# MIMXRT1011 register map
Vendor: nxp.com; File version: 1.0
CPU: CM7 r0p1, little endian, MPU, FPU, VTOR, 4 interrupt priority bits
Registers are 32-bit, read-write, reset 0x0 unless marked. A register's access mark holds for its fields unless they carry their own. Offsets are from the block's base; [hi:lo] are bit positions; {n}, {i} and the like mark numbered series; 'fields as' and 'values as' point back to an identical list.

## FLEXSPI
Base 0x400A0000
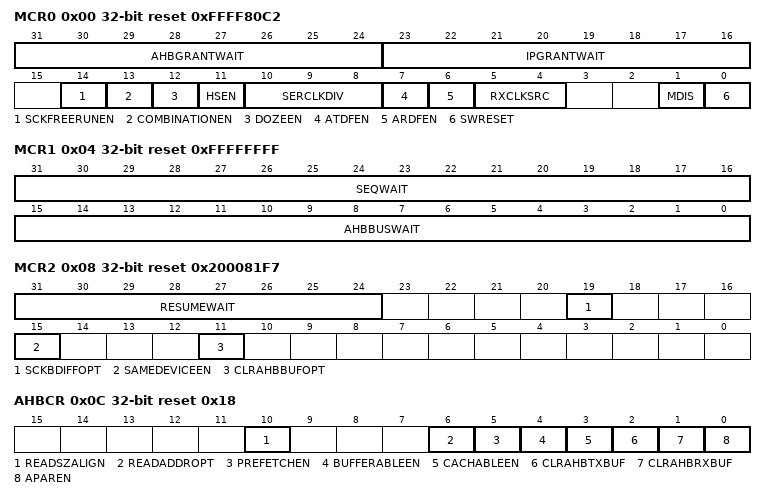
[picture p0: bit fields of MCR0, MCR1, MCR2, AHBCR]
0x00 MCR0 reset 0xFFFF80C2 — Module Control Register 0
  [31:24] AHBGRANTWAIT — Timeout wait cycle for AHB command grant.
  [23:16] IPGRANTWAIT — Time out wait cycle for IP command grant.
  [14] SCKFREERUNEN — This bit is used to force SCLK output free-running. For FPGA applications, external device may use SCLK as reference clock to its internal PLL. If SCLK free-running is enabled, data sampling with loopback clock from SCLK pad is not supported (MCR0[RXCLKSRC]=2).
    0=DISABLE; 1=ENABLE
  [13] COMBINATIONEN — This bit is to support Flash Octal mode access by combining Port A and B Data pins (A_DATA[3:0] and B_DATA[3:0]), when Port A and Port B are of 4 bit data width.
    0=DISABLE; 1=ENABLE
  [12] DOZEEN — Doze mode enable bit
    0=Doze mode support disabled. AHB clock and serial clock will not be gated off when there is doze mode request from system.; 1=Doze mode support enabled. AHB clock and serial clock will be gated off when there is doze mode request from system.
  [11] HSEN — Half Speed Serial Flash access Enable.
    0=Disable divide by 2 of serial flash clock for half speed commands; 1=Enable divide by 2 of serial flash clock for half speed commands
  [10:8] SERCLKDIV — The serial root clock could be divided inside FlexSPI . See Clocks section for more details on clocking.
    {v}=Divided by {v+1} (v=0..7)
  [7] ATDFEN — Enable AHB bus Write Access to IP TX FIFO.
    0=IP TX FIFO should be written by IP Bus. AHB Bus write access to IP TX FIFO memory space will get bus error response.; 1=IP TX FIFO should be written by AHB Bus. IP Bus write access to IP TX FIFO memory space will be ignored but no bus error response.
  [6] ARDFEN — Enable AHB bus Read Access to IP RX FIFO.
    0=IP RX FIFO should be read by IP Bus. AHB Bus read access to IP RX FIFO memory space will get bus error response.; 1=IP RX FIFO should be read by AHB Bus. IP Bus read access to IP RX FIFO memory space will always return data zero but no bus error response.
  [5:4] RXCLKSRC — Sample Clock source selection for Flash Reading
    0=Dummy Read strobe generated by FlexSPI Controller and loopback internally; 1=Dummy Read strobe generated by FlexSPI Controller and loopback from DQS pad; 3=Flash provided Read strobe and input from DQS pad
  [1] MDIS — Module Disable
  [0] SWRESET — Software Reset
0x04 MCR1 reset 0xFFFFFFFF — Module Control Register 1
  [31:16] SEQWAIT — Command Sequence Execution will timeout and abort after SEQWAIT * 1024 Serial Root Clock cycles
  [15:0] AHBBUSWAIT — AHB Read/Write access to Serial Flash Memory space will timeout if not data received from Flash or data not transmitted after AHBBUSWAIT * 1024 ahb clock cycles, AHB Bus will get an error response
0x08 MCR2 reset 0x200081F7 — Module Control Register 2
  [31:24] RESUMEWAIT — Wait cycle (in AHB clock cycle) for idle state before suspended command sequence resumed.
  [19] SCKBDIFFOPT — B_SCLK pad can be used as A_SCLK differential clock output (inverted clock to A_SCLK). In this case, port B flash access is not available. After changing the value of this field, MCR0[SWRESET] should be set.
    0=B_SCLK pad is used as port B SCLK clock output. Port B flash access is available.; 1=B_SCLK pad is used as port A SCLK inverted clock output (Differential clock to A_SCLK). Port B flash access is not available.
  [15] SAMEDEVICEEN — All external devices are same devices (both in types and size) for A1/A2/B1/B2.
    0=individual_parallel (In Individual mode, FLSHA1CRx/FLSHA2CRx/FLSHB1CRx/FLSHB2CRx register setting will be applied to Flash A1/A2/B1/B2 separately. In Parallel mode, FLSHA1CRx register setting will be applied to Flash A1 and B1, FLSHA2CRx register setting will be applied to Flash A2 and B2. FLSHB1CRx/FLSHB2CRx register settings will be ignored.); 1=ENABLE (FLSHA1CR0/FLSHA1CR1/FLSHA1CR2 register settings will be applied to Flash A1/A2/B1/B2. FLSHA2CRx/FLSHB1CRx/FLSHB2CRx will be ignored.)
  [11] CLRAHBBUFOPT — This bit determines whether AHB RX Buffer and AHB TX Buffer will be cleaned automatically when FlexSPI returns STOP mode ACK. Software should set this bit if AHB RX Buffer or AHB TX Buffer will be powered off in STOP mode. Otherwise AHB read access after exiting STOP mode may hit AHB RX Buffer or AHB TX Buffer but their data entries are invalid.
    0=AHB RX/TX Buffer will not be cleaned automatically when FlexSPI return Stop mode ACK; 1=AHB RX/TX Buffer will be cleaned automatically when FlexSPI return Stop mode ACK
0x0C AHBCR reset 0x18 — AHB Bus Control Register
  [10] READSZALIGN — AHB Read Size Alignment
    0=AHB read size will be decided by other register setting like PREFETCH_EN,OTFAD_EN; 1=AHB read size to up size to 8 bytes aligned, no prefetching
  [6] READADDROPT — AHB Read Address option bit. This option bit is intend to remove AHB burst start address alignment limitation.
    0=There is AHB read burst start address alignment limitation when flash is accessed in parallel mode or flash is word-addressable; 1=There is no AHB read burst start address alignment limitation. FlexSPI will fetch more data than AHB burst required to meet the alignment requirement.
  [5] PREFETCHEN — AHB Read Prefetch Enable.
  [4] BUFFERABLEEN — Enable AHB bus bufferable write access support. This field affects the last beat of AHB write access, refer for more details about AHB bufferable write.
    0=Disabled. For all AHB write access (no matter bufferable or non-bufferable ), FlexSPI will return AHB Bus ready after all data is transmitted to External device and AHB command finished.; 1=Enabled. For AHB bufferable write access, FlexSPI will return AHB Bus ready when the AHB command is granted by arbitrator and will not wait for AHB command finished.
  [3] CACHABLEEN — Enable AHB bus cachable read access support.
    0=Disabled. When there is AHB bus cachable read access, FlexSPI will not check whether it hit AHB TX Buffer.; 1=Enabled. When there is AHB bus cachable read access, FlexSPI will check whether it hit AHB TX Buffer first.
  [2] CLRAHBTXBUF — Clear the status/pointers of AHB TX Buffer. Auto-cleared. For internal use only.
  [1] CLRAHBRXBUF — Clear the status/pointers of AHB RX Buffer. Auto-cleared.
  [0] APAREN — Parallel mode enabled for AHB triggered Command (both read and write) .
    0=individual (Flash will be accessed in Individual mode.); 1=ENABLE (Flash will be accessed in Parallel mode.)
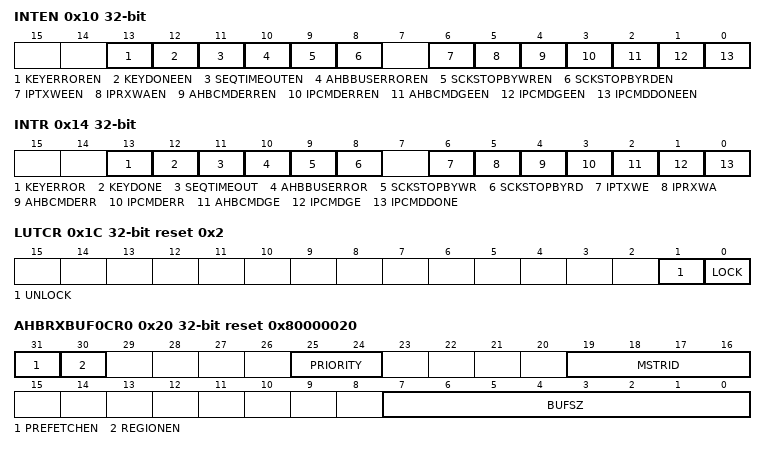
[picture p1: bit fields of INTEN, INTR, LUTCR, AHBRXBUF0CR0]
0x10 INTEN — Interrupt Enable Register
  [13] KEYERROREN — OTFAD key blob processing error interrupt enable.Refer Interrupts chapter for more details.
  [12] KEYDONEEN — OTFAD key blob processing done interrupt enable.Refer Interrupts chapter for more details.
  [11] SEQTIMEOUTEN — Sequence execution timeout interrupt enable.Refer Interrupts chapter for more details.
  [10] AHBBUSERROREN — AHB Bus error interrupt enable.Refer Interrupts chapter for more details.
  [9] SCKSTOPBYWREN — SCLK is stopped during command sequence because Async TX FIFO empty interrupt enable.
  [8] SCKSTOPBYRDEN — SCLK is stopped during command sequence because Async RX FIFO full interrupt enable.
  [6] IPTXWEEN — IP TX FIFO WaterMark empty interrupt enable.
  [5] IPRXWAEN — IP RX FIFO WaterMark available interrupt enable.
  [4] AHBCMDERREN — AHB triggered Command Sequences Error Detected interrupt enable.
  [3] IPCMDERREN — IP triggered Command Sequences Error Detected interrupt enable.
  [2] AHBCMDGEEN — AHB triggered Command Sequences Grant Timeout interrupt enable.
  [1] IPCMDGEEN — IP triggered Command Sequences Grant Timeout interrupt enable.
  [0] IPCMDDONEEN — IP triggered Command Sequences Execution finished interrupt enable.
0x14 INTR — Interrupt Register
  [13] KEYERROR ro — OTFAD key blob processing error interrupt.
  [12] KEYDONE write-1-clears — OTFAD key blob processing done interrupt.
  [11] SEQTIMEOUT write-1-clears — Sequence execution timeout interrupt.
  [10] AHBBUSERROR write-1-clears — AHB Bus timeout or AHB bus illegal access Flash during OTFAD key blob processing interrupt.
  [9] SCKSTOPBYWR write-1-clears — SCLK is stopped during command sequence because Async TX FIFO empty interrupt.
  [8] SCKSTOPBYRD write-1-clears — SCLK is stopped during command sequence because Async RX FIFO full interrupt.
  [6] IPTXWE write-1-clears — IP TX FIFO watermark empty interrupt.
  [5] IPRXWA write-1-clears — IP RX FIFO watermark available interrupt.
  [4] AHBCMDERR write-1-clears — AHB triggered Command Sequences Error Detected interrupt. When an error detected for AHB command, this command will be ignored and not executed at all.
  [3] IPCMDERR write-1-clears — IP triggered Command Sequences Error Detected interrupt. When an error detected for IP command, this command will be ignored and not executed at all.
  [2] AHBCMDGE write-1-clears — AHB triggered Command Sequences Grant Timeout interrupt.
  [1] IPCMDGE write-1-clears — IP triggered Command Sequences Grant Timeout interrupt.
  [0] IPCMDDONE write-1-clears — IP triggered Command Sequences Execution finished interrupt. This interrupt is also generated when there is IPCMDGE or IPCMDERR interrupt generated.
0x18 LUTKEY reset 0x5AF05AF0
  [31:0] KEY — The Key to lock or unlock LUT.
0x1C LUTCR reset 0x2 — LUT Control Register
  [1] UNLOCK — Unlock LUT
  [0] LOCK — Lock LUT
0x20 AHBRXBUF0CR0 reset 0x80000020 — AHB RX Buffer 0 Control Register 0
  [31] PREFETCHEN — AHB Read Prefetch Enable for current AHB RX Buffer corresponding Master.
  [30] REGIONEN — AHB RX Buffer address region funciton enable
  [25:24] PRIORITY — This priority for AHB Master Read which this AHB RX Buffer is assigned. 7 is the highest priority, 0 the lowest.
  [19:16] MSTRID — This AHB RX Buffer is assigned according to AHB Master with ID (MSTR_ID).
  [7:0] BUFSZ — AHB RX Buffer Size in 64 bits.
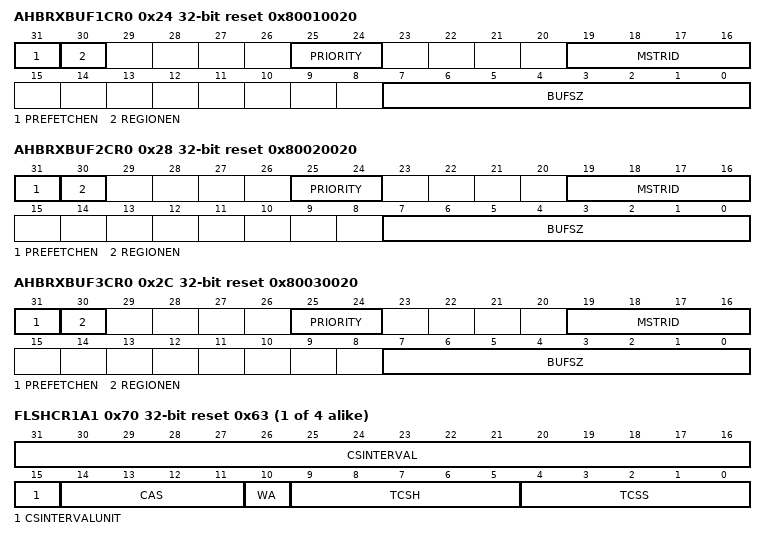
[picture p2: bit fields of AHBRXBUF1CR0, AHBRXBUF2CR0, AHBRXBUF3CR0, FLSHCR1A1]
0x24 AHBRXBUF1CR0 reset 0x80010020 — AHB RX Buffer 1 Control Register 0
  fields as AHBRXBUF0CR0
0x28 AHBRXBUF2CR0 reset 0x80020020 — AHB RX Buffer 2 Control Register 0
  fields as AHBRXBUF0CR0
0x2C AHBRXBUF3CR0 reset 0x80030020 — AHB RX Buffer 3 Control Register 0
  fields as AHBRXBUF0CR0
0x60 FLSHA1CR0 reset 0x10000 — Flash Control Register 0
  [22:0] FLSHSZ — Flash Size in KByte.
0x64 FLSHA2CR0 reset 0x10000 — Flash Control Register 0
  [22:0] FLSHSZ — Flash Size in KByte.
0x68 FLSHB1CR0 reset 0x10000 — Flash Control Register 0
  [22:0] FLSHSZ — Flash Size in KByte.
0x6C FLSHB2CR0 reset 0x10000 — Flash Control Register 0
  [22:0] FLSHSZ — Flash Size in KByte.
0x70 FLSHCR1{x} (x=A1,A2,B1,B2; step 0x4) reset 0x63 — Flash Control Register 1
  [31:16] CSINTERVAL — This field is used to set the minimum interval between flash device Chip selection deassertion and flash device Chip selection assertion. If external flash has a limitation on the interval between command sequences, this field should be set accordingly. If there is no limitation, set this field with value 0x0.
  [15] CSINTERVALUNIT
    0=The CS interval unit is 1 serial clock cycle; 1=The CS interval unit is 256 serial clock cycle
  [14:11] CAS — Column Address Size.
  [10] WA — Word Addressable.
  [9:5] TCSH — Serial Flash CS Hold time.
  [4:0] TCSS — Serial Flash CS setup time.
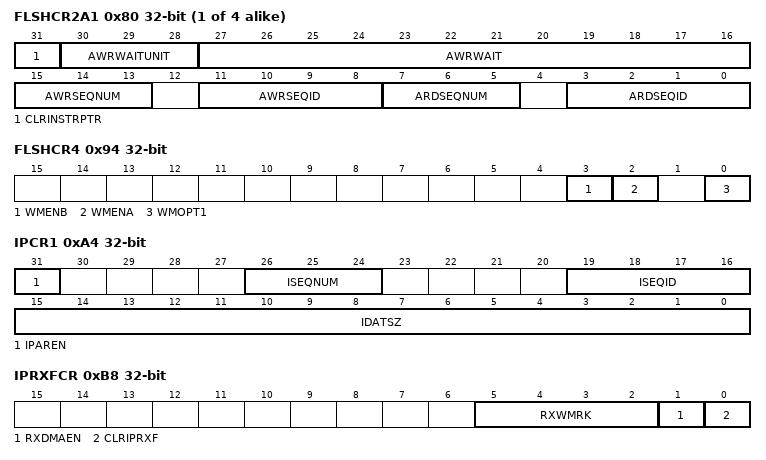
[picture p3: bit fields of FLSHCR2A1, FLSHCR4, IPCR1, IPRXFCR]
0x80 FLSHCR2{x} (x=A1,A2,B1,B2; step 0x4) — Flash Control Register 2
  [31] CLRINSTRPTR — Clear the instruction pointer which is internally saved pointer by JMP_ON_CS. Refer Programmable Sequence Engine for details.
  [30:28] AWRWAITUNIT
    0=The AWRWAIT unit is 2 ahb clock cycle; 1=The AWRWAIT unit is 8 ahb clock cycle; 2=The AWRWAIT unit is 32 ahb clock cycle; 3=The AWRWAIT unit is 128 ahb clock cycle; 4=The AWRWAIT unit is 512 ahb clock cycle; 5=The AWRWAIT unit is 2048 ahb clock cycle; 6=The AWRWAIT unit is 8192 ahb clock cycle; 7=The AWRWAIT unit is 32768 ahb clock cycle
  [27:16] AWRWAIT — For certain devices (such as FPGA), it need some time to write data into internal memory after the command sequences finished on FlexSPI interface
  [15:13] AWRSEQNUM — Sequence Number for AHB Write triggered Command.
  [11:8] AWRSEQID — Sequence Index for AHB Write triggered Command.
  [7:5] ARDSEQNUM — Sequence Number for AHB Read triggered Command in LUT.
  [3:0] ARDSEQID — Sequence Index for AHB Read triggered Command in LUT.
0x94 FLSHCR4 — Flash Control Register 4
  [3] WMENB — Write mask enable bit for flash device on port B. When write mask function is needed for memory device on port B, this bit must be set.
    0=Write mask is disabled, DQS(RWDS) pin will be un-driven when writing to external device; 1=Write mask is enabled, DQS(RWDS) pin will be driven by FlexSPI as write mask output when writing to external device
  [2] WMENA — Write mask enable bit for flash device on port A. When write mask function is needed for memory device on port A, this bit must be set.
    values as WMENB
  [0] WMOPT1 — Write mask option bit 1. This option bit could be used to remove AHB write burst start address alignment limitation.
    0=DISABLE (DQS pin will be used as Write Mask when writing to external device. There is no limitation on AHB write burst start address alignment when flash is accessed in individual mode.); 1=ENABLE (DQS pin will not be used as Write Mask when writing to external device. There is limitation on AHB write burst start address alignment when flash is accessed in individual mode.)
0xA0 IPCR0 — IP Control Register 0
  [31:0] SFAR — Serial Flash Address for IP command.
0xA4 IPCR1 — IP Control Register 1
  [31] IPAREN — Parallel mode Enabled for IP command.
    0=DISABLE (Flash will be accessed in Individual mode.); 1=ENABLE (Flash will be accessed in Parallel mode.)
  [26:24] ISEQNUM — Sequence Number for IP command: ISEQNUM+1.
  [19:16] ISEQID — Sequence Index in LUT for IP command.
  [15:0] IDATSZ — Flash Read/Program Data Size (in Bytes) for IP command.
0xB0 IPCMD — IP Command Register
  [0] TRG — Setting this bit will trigger an IP Command.
0xB8 IPRXFCR — IP RX FIFO Control Register
  [5:2] RXWMRK — Watermark level is (RXWMRK+1)*64 Bits.
  [1] RXDMAEN — IP RX FIFO reading by DMA enabled.
    0=IP RX FIFO would be read by processor; 1=IP RX FIFO would be read by DMA
  [0] CLRIPRXF — Clear all valid data entries in IP RX FIFO.
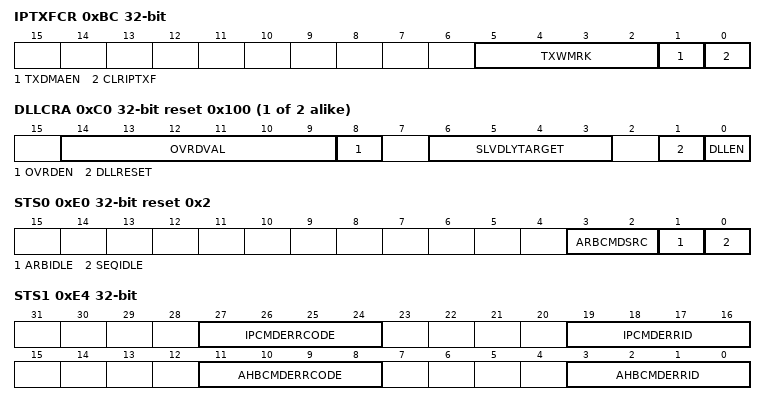
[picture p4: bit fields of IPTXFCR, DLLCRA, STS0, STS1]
0xBC IPTXFCR — IP TX FIFO Control Register
  [5:2] TXWMRK — Watermark level is (TXWMRK+1)*64 Bits.
  [1] TXDMAEN — IP TX FIFO filling by DMA enabled.
    0=IP TX FIFO would be filled by processor; 1=IP TX FIFO would be filled by DMA
  [0] CLRIPTXF — Clear all valid data entries in IP TX FIFO.
0xC0 DLLCR{x} (x=A,B; step 0x4) reset 0x100 — DLL Control Register 0
  [14:9] OVRDVAL — Slave clock delay line delay cell number selection override value.
  [8] OVRDEN — Slave clock delay line delay cell number selection override enable.
  [6:3] SLVDLYTARGET — The delay target for slave delay line is: ((SLVDLYTARGET+1) * 1/32 * clock cycle of reference clock (serial root clock). If serial root clock is >= 100 MHz, DLLEN set to 0x1, OVRDEN set to =0x0, then SLVDLYTARGET setting of 0xF is recommended.
  [1] DLLRESET — Software could force a reset on DLL by setting this field to 0x1. This will cause the DLL to lose lock and re-calibrate to detect an ref_clock half period phase shift. The reset action is edge triggered, so software need to clear this bit after set this bit (no delay limitation).
  [0] DLLEN — DLL calibration enable.
0xE0 STS0 ro reset 0x2 — Status Register 0
  [3:2] ARBCMDSRC — This status field indicates the trigger source of current command sequence granted by arbitrator. This field value is meaningless when ARB_CTL is not busy (STS0[ARBIDLE]=0x1).
    0=Triggered by AHB read command (triggered by AHB read); 1=Triggered by AHB write command (triggered by AHB Write); 2=Triggered by IP command (triggered by setting register bit IPCMD.TRG); 3=Triggered by suspended command (resumed)
  [1] ARBIDLE — This status bit indicates the state machine in ARB_CTL is busy and there is command sequence granted by arbitrator and not finished yet on FlexSPI interface. When ARB_CTL state (ARBIDLE=0x1) is idle, there will be no transaction on FlexSPI interface also (SEQIDLE=0x1). So this bit should be polled to wait for FlexSPI controller become idle instead of SEQIDLE.
  [0] SEQIDLE — This status bit indicates the state machine in SEQ_CTL is idle and there is command sequence executing on FlexSPI interface.
0xE4 STS1 ro — Status Register 1
  [27:24] IPCMDERRCODE — Indicates the Error Code when IP command Error detected. This field will be cleared when INTR[IPCMDERR] is write-1-clear(w1c).
    0=No error; 2=IP command with JMP_ON_CS instruction used in the sequence; 3=There is unknown instruction opcode in the sequence; 4=Instruction DUMMY_SDR/DUMMY_RWDS_SDR used in DDR sequence; 5=Instruction DUMMY_DDR/DUMMY_RWDS_DDR used in SDR sequence; 6=Flash access start address exceed the whole flash address range (A1/A2/B1/B2); 14=Sequence execution timeout; 15=Flash boundary crossed
  [19:16] IPCMDERRID — Indicates the sequence Index when IP command error detected. This field will be cleared when INTR[IPCMDERR] is write-1-clear(w1c).
  [11:8] AHBCMDERRCODE — Indicates the Error Code when AHB command Error detected. This field will be cleared when INTR[AHBCMDERR] is write-1-clear(w1c).
    0=No error; 2=AHB Write command with JMP_ON_CS instruction used in the sequence; 3=There is unknown instruction opcode in the sequence; 4=Instruction DUMMY_SDR/DUMMY_RWDS_SDR used in DDR sequence; 5=Instruction DUMMY_DDR/DUMMY_RWDS_DDR used in SDR sequence; 14=Sequence execution timeout
  [3:0] AHBCMDERRID — Indicates the sequence index when an AHB command error is detected. This field will be cleared when INTR[AHBCMDERR] is write-1-clear(w1c).
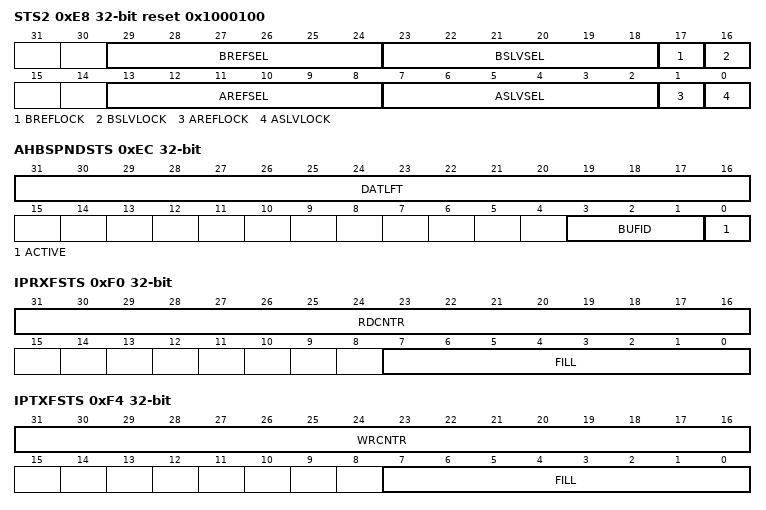
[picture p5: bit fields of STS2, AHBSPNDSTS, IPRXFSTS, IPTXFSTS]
0xE8 STS2 ro reset 0x1000100 — Status Register 2
  [29:24] BREFSEL — Flash B sample clock reference delay line delay cell number selection.
  [23:18] BSLVSEL — Flash B sample clock slave delay line delay cell number selection.
  [17] BREFLOCK — Flash B sample clock reference delay line locked.
  [16] BSLVLOCK — Flash B sample clock slave delay line locked.
  [13:8] AREFSEL — Flash A sample clock reference delay line delay cell number selection.
  [7:2] ASLVSEL — Flash A sample clock slave delay line delay cell number selection .
  [1] AREFLOCK — Flash A sample clock reference delay line locked.
  [0] ASLVLOCK — Flash A sample clock slave delay line locked.
0xEC AHBSPNDSTS ro — AHB Suspend Status Register
  [31:16] DATLFT — Left Data size for suspended command sequence (in byte).
  [3:1] BUFID — AHB RX BUF ID for suspended command sequence.
  [0] ACTIVE — Indicates if an AHB read prefetch command sequence has been suspended.
0xF0 IPRXFSTS ro — IP RX FIFO Status Register
  [31:16] RDCNTR — Total Read Data Counter: RDCNTR * 64 Bits.
  [7:0] FILL — Fill level of IP RX FIFO.
0xF4 IPTXFSTS ro — IP TX FIFO Status Register
  [31:16] WRCNTR — Total Write Data Counter: WRCNTR * 64 Bits.
  [7:0] FILL — Fill level of IP TX FIFO.
{0x100+4i} RFDR[{i}] (i=0..31) ro — IP RX FIFO Data Register x
  [31:0] RXDATA
{0x180+4i} TFDR[{i}] (i=0..31) wo — IP TX FIFO Data Register x
  [31:0] TXDATA
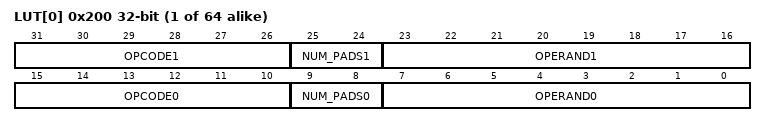
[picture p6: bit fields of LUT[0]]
{0x200+4i} LUT[{i}] (i=0..63) reset not defined — LUT x
  [31:26] OPCODE1
  [25:24] NUM_PADS1
  [23:16] OPERAND1
  [15:10] OPCODE0 — OPCODE
  [9:8] NUM_PADS0
  [7:0] OPERAND0
